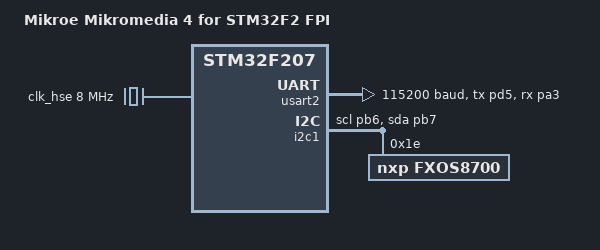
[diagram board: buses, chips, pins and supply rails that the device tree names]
/*
 * Copyright (c) 2024 Ian Morris
 *
 * SPDX-License-Identifier: Apache-2.0
 */

 /dts-v1/;
#include <st/f2/stm32f207Xg.dtsi>
#include <st/f2/stm32f207z(c-e-f-g)tx-pinctrl.dtsi>

/ {
	model = "Mikroe Mikromedia 4 for STM32F2 FPI";
	compatible = "st,stm32f207";

	aliases {
		magn0 = &fxos8700;
		accel0 = &fxos8700;
	};

	chosen {
		zephyr,console = &usart2;
		zephyr,shell-uart = &usart2;
		zephyr,sram = &sram0;
		zephyr,flash = &flash0;
	};
};

&clk_hse {
	hse-bypass;
	clock-frequency = <DT_FREQ_M(8)>; /* STLink 8MHz clock */
	status = "okay";
};

&pll {
	div-m = <8>;
	mul-n = <240>;
	div-p = <2>;
	div-q = <5>;
	clocks = <&clk_hse>;
	status = "okay";
};

&rcc {
	clocks = <&pll>;
	clock-frequency = <DT_FREQ_M(120)>;
	ahb-prescaler = <1>;
	apb1-prescaler = <4>;
	apb2-prescaler = <2>;
};

&usart2 {
	pinctrl-0 = <&usart2_tx_pd5 &usart2_rx_pa3>;
	pinctrl-names = "default";
	current-speed = <115200>;
	status = "okay";
};

&i2c1 {
	pinctrl-0 = <&i2c1_scl_pb6 &i2c1_sda_pb7>;
	pinctrl-names = "default";
	status = "okay";

	fxos8700: fxos8700@1e {
		compatible = "nxp,fxos8700";
		reg = <0x1e>;
	};
};
